VERSION ""

NS_ :

BS_:

BU_: BCW FCA GateWay SCC MDPS

BO_ 305 GW_BCM_Side_Road_State: 1 GateWay
 SG_ Side_Road_State : 0|1@1+ (1,0) [0|1] "" Vector__XXX

BO_ 304 GW_BCM_Rear_Vehicle_State: 1 GateWay
 SG_ Rear_Vehicle_state : 0|1@1+ (1,0) [0|1] "" Vector__XXX

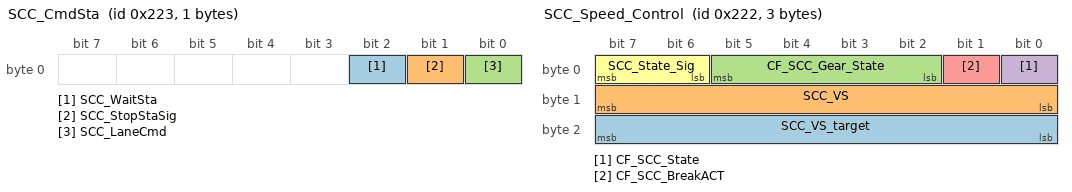
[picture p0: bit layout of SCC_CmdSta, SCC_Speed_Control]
BO_ 547 SCC_CmdSta: 1 SCC
 SG_ SCC_WaitSta : 2|1@1+ (1,0) [0|1] "" Vector__XXX
 SG_ SCC_StopStaSig : 1|1@1+ (1,0) [0|1] "" Vector__XXX
 SG_ SCC_LaneCmd : 0|1@1+ (1,0) [0|1] "" Vector__XXX

BO_ 1072 GW_BCM_WheelSpd_FL: 1 GateWay
 SG_ WheelSpd_FL : 0|8@1+ (1,0) [0|255] "" Vector__XXX

BO_ 1536 VCU_Emergency_Act: 1 GateWay
 SG_ Emergency_Act : 0|1@1+ (1,0) [0|1] ""  SCC

BO_ 88 BCW_NM_Flag: 1 BCW
 SG_ BCW_Flag : 0|1@1+ (1,1) [0|1] ""  GateWay

BO_ 87 FCA_NM_Flag: 1 FCA
 SG_ FCA_Flag : 0|1@1+ (1,1) [0|1] ""  GateWay

BO_ 73 GW_NM_BCW: 1 GateWay
 SG_ NmSleepCmd_BCW : 0|1@1+ (1,0) [0|1] ""  BCW

BO_ 72 GW_NM_FCA: 1 GateWay
 SG_ NmSleepCmd_FCA : 0|1@1+ (1,0) [0|1] ""  FCA

BO_ 1056 EMS_Engine_Data: 2 GateWay
 SG_ EMS_RPM_Data : 0|16@1+ (0.25,0) [0|16383.75] "rpm"  MDPS

BO_ 89 SCC_NM_Flag: 1 SCC
 SG_ SCC_Flag : 0|1@1+ (1,1) [0|1] ""  GateWay

BO_ 86 MDPS_NM_Flag: 1 MDPS
 SG_ MDPS_Flag : 0|1@1+ (1,1) [0|1] ""  GateWay

BO_ 71 GW_NM_SCC: 1 GateWay
 SG_ NmSleepCmd_SCC : 0|1@1+ (1,0) [0|1] ""  SCC

BO_ 70 GW_NM_MDPS: 1 GateWay
 SG_ NmSleepCmd_MDPS : 0|1@1+ (1,0) [0|1] ""  MDPS

BO_ 50 VCU_IGN1: 1 GateWay
 SG_ IGN_State : 0|1@1+ (1,0) [0|1] ""  MDPS

BO_ 1041 EPB_Press_Data: 2 GateWay
 SG_ EPB_CylinderPress : 1|12@1+ (0.1,0) [0|409.5] "Bar"  SCC
 SG_ EPB_CylinderState : 0|1@1+ (1,0) [0|1] ""  SCC

BO_ 1040 EPB_State_Data: 1 GateWay
 SG_ EPB_ACT : 1|1@1+ (1,0) [0|1] ""  SCC
 SG_ EPB_State : 0|1@1+ (1,0) [0|1] ""  SCC

BO_ 1024 TCU_Gear_Data: 1 GateWay
 SG_ TCU_GearState : 0|1@1+ (1,0) [0|1] ""  SCC
 SG_ TCU_GearType : 1|4@1+ (1,0) [0|15] ""  SCC,MDPS

BO_ 560 BCW_Data: 1 BCW
 SG_ BCW_LR : 0|2@1+ (1,0) [0|2] ""  SCC,GateWay
 SG_ BCWState : 2|2@1+ (1,0) [0|3] ""  SCC,GateWay

BO_ 561 FCA_Data: 1 FCA
 SG_ FCAState : 0|2@1+ (1,0) [0|3] ""  SCC,GateWay

BO_ 546 SCC_Speed_Control: 3 SCC
 SG_ SCC_VS_target : 16|8@1+ (1,0) [0|254] "km/h"  GateWay
 SG_ SCC_VS : 8|8@1+ (1,0) [0|254] "km/h"  GateWay
 SG_ CF_SCC_Gear_State : 2|4@1+ (1,0) [0|15] ""  GateWay
 SG_ CF_SCC_State : 0|1@1+ (1,0) [0|1] ""  GateWay
 SG_ CF_SCC_BreakACT : 1|1@1+ (1,0) [0|1] ""  GateWay
 SG_ SCC_State_Sig : 6|2@1+ (1,0) [0|4] ""  GateWay

BO_ 545 SCC_E_stop: 1 SCC
 SG_ CF_Estop : 0|1@1+ (1,0) [0|1] ""  GateWay

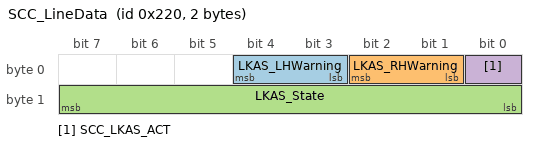
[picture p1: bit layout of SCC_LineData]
BO_ 544 SCC_LineData: 2 SCC
 SG_ LKAS_LHWarning : 3|2@1+ (1,0) [0|3] ""  GateWay
 SG_ LKAS_RHWarning : 1|2@1+ (1,0) [0|3] ""  GateWay
 SG_ LKAS_State : 8|8@1+ (1,0) [0|7] ""  GateWay
 SG_ SCC_LKAS_ACT : 0|1@1+ (1,0) [0|1] ""  GateWay

BO_ 529 MDPS_Col_Tq: 2 MDPS
 SG_ ColTq : 0|11@1+ (1,-1024) [-1024|1024] ""  GateWay

BO_ 528 MDPS_Out_Tq: 2 MDPS
 SG_ OutTq : 0|12@1+ (0.1,-204.8) [-204.8|204.7] ""  GateWay

BO_ 513 MDPS_Steering_Tq: 2 MDPS
 SG_ sig_SteeringTq : 0|12@1+ (0.01,-20.48) [-20.48|20.47] "Nm"  GateWay

BO_ 512 MDPS_Steering_Angle: 2 MDPS
 SG_ SteeringAngle : 0|16@1- (0.1,0) [-3276.8|3276.7] "Deg"  GateWay

BA_DEF_  "BusType" STRING ;
BA_DEF_DEF_  "BusType" "CAN";
